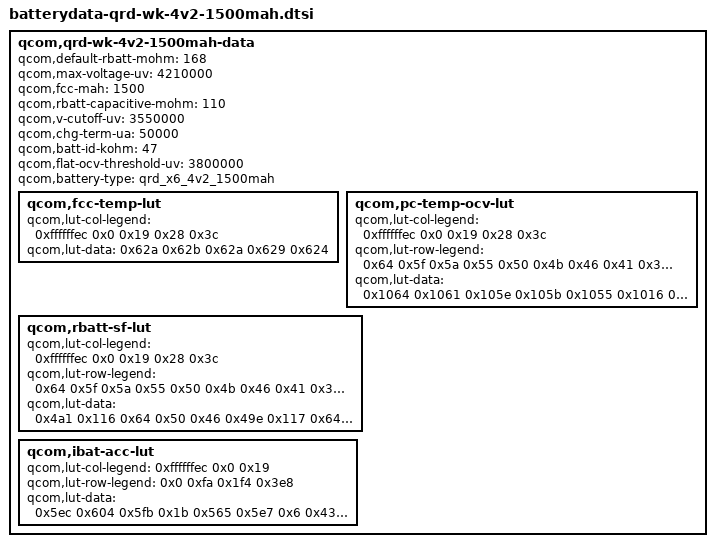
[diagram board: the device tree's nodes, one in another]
/* Copyright (c) 2014, The Linux Foundation. All rights reserved.
 *
 * This program is free software; you can redistribute it and/or modify
 * it under the terms of the GNU General Public License version 2 and
 * only version 2 as published by the Free Software Foundation.
 *
 * This program is distributed in the hope that it will be useful,
 * but WITHOUT ANY WARRANTY; without even the implied warranty of
 * MERCHANTABILITY or FITNESS FOR A PARTICULAR PURPOSE.  See the
 * GNU General Public License for more details.
 */

qcom,qrd-wk-4v2-1500mah-data {
	qcom,default-rbatt-mohm = <168>;
	qcom,max-voltage-uv = <4210000>;
	qcom,fcc-mah = <1500>;
	qcom,rbatt-capacitive-mohm = <110>;
	qcom,v-cutoff-uv = <3550000>;
	qcom,chg-term-ua = <50000>;
	qcom,batt-id-kohm = <47>;
	qcom,flat-ocv-threshold-uv = <3800000>;
	qcom,battery-type = "qrd_x6_4v2_1500mah";

	qcom,fcc-temp-lut {
		qcom,lut-col-legend = <0xffffffec 0x0 0x19 0x28 0x3c>;
		qcom,lut-data = <0x62a 0x62b 0x62a 0x629 0x624>;
	};

	qcom,pc-temp-ocv-lut {
		qcom,lut-col-legend = <0xffffffec 0x0 0x19 0x28 0x3c>;
		qcom,lut-row-legend = <0x64 0x5f 0x5a 0x55 0x50 0x4b 0x46 0x41 0x3c 0x37 0x32 0x2d 0x28 0x23 0x1e 0x19 0x14 0x10 0xd 0xb 0xa 0x9 0x8 0x7 0x6 0x5 0x4 0x3 0x2 0x1 0x0>;
		qcom,lut-data = <0x1064 0x1061 0x105e 0x105b 0x1055 0x1016 0x1022 0x1022 0x1020 0x101c 0xfdf 0xff0 0xff1 0xfef 0xfec 0xfa8 0xfc2 0xfc5 0xfc3 0xfc0 0xf76 0xf95 0xf9d 0xf9b 0xf98 0xf50 0xf6e 0xf79 0xf78 0xf74 0xf2d 0xf4a 0xf5a 0xf58 0xf54 0xf0d 0xf29 0xf3b 0xf3b 0xf37 0xef2 0xf0c 0xf19 0xf1b 0xf19 0xedc 0xef3 0xef7 0xef8 0xef6 0xecb 0xedd 0xedf 0xede 0xedd 0xebd 0xecc 0xece 0xece 0xecc 0xeaf 0xebe 0xec2 0xec2 0xec0 0xea1 0xeb3 0xeba 0xeb8 0xeb5 0xe92 0xea7 0xeb3 0xeae 0xea7 0xe81 0xe96 0xea6 0xe9f 0xe91 0xe6d 0xe84 0xe93 0xe8a 0xe7d 0xe59 0xe79 0xe78 0xe70 0xe64 0xe46 0xe6e 0xe61 0xe58 0xe4c 0xe34 0xe66 0xe5b 0xe53 0xe48 0xe29 0xe61 0xe58 0xe51 0xe46 0xe1e 0xe5b 0xe56 0xe4f 0xe44 0xe10 0xe55 0xe53 0xe4c 0xe41 0xdff 0xe4c 0xe4e 0xe47 0xe3c 0xdea 0xe40 0xe45 0xe3d 0xe30 0xdce 0xe2b 0xe30 0xe25 0xe13 0xdab 0xe05 0xe04 0xdfa 0xde6 0xd78 0xdce 0xdc6 0xdbc 0xda9 0xd27 0xd7e 0xd73 0xd6a 0xd57 0xca3 0xcfd 0xcf9 0xceb 0xcd7 0xbc0 0xbb8 0xbd9 0xbb8 0xbb8>;
	};

	qcom,rbatt-sf-lut {
		qcom,lut-col-legend = <0xffffffec 0x0 0x19 0x28 0x3c>;
		qcom,lut-row-legend = <0x64 0x5f 0x5a 0x55 0x50 0x4b 0x46 0x41 0x3c 0x37 0x32 0x2d 0x28 0x23 0x1e 0x19 0x14 0x10 0xd 0xb 0xa 0x9 0x8 0x7 0x6 0x5 0x4 0x3 0x2 0x1>;
		qcom,lut-data = <0x4a1 0x116 0x64 0x50 0x46 0x49e 0x117 0x64 0x50 0x46 0x470 0x11c 0x66 0x51 0x47 0x445 0x120 0x69 0x53 0x48 0x427 0x11f 0x6d 0x55 0x4a 0x41d 0x11c 0x72 0x58 0x4c 0x415 0x119 0x78 0x5c 0x50 0x415 0x115 0x7e 0x61 0x53 0x419 0x113 0x77 0x62 0x55 0x425 0x112 0x6a 0x58 0x4e 0x43b 0x113 0x65 0x52 0x49 0x458 0x116 0x66 0x53 0x4a 0x47e 0x11a 0x68 0x56 0x4d 0x4ab 0x121 0x6c 0x58 0x50 0x4e4 0x128 0x70 0x58 0x4f 0x527 0x12b 0x71 0x57 0x4b 0x56d 0x139 0x71 0x56 0x4b 0x582 0x149 0x6c 0x55 0x4b 0x57c 0x14b 0x67 0x51 0x49 0x5eb 0x15c 0x69 0x53 0x4b 0x658 0x169 0x6b 0x56 0x4c 0x709 0x177 0x6f 0x58 0x4e 0x7fe 0x18b 0x74 0x5a 0x4f 0x956 0x1a4 0x79 0x5d 0x51 0xb4a 0x1c3 0x7d 0x5e 0x50 0xea1 0x1ee 0x7d 0x5c 0x4e 0x13c7 0x231 0x7b 0x5b 0x4f 0x91fa 0x2b8 0x82 0x60 0x53 0x2fc7 0x3d0 0x92 0x69 0x58 0x5f8f 0x728 0xc0 0x86 0x69>;
	};

	qcom,ibat-acc-lut {
		qcom,lut-col-legend = <0xffffffec 0x0 0x19>;
		qcom,lut-row-legend = <0x0 0xfa 0x1f4 0x3e8>;
		qcom,lut-data = <0x5ec 0x604 0x5fb 0x1b 0x565 0x5e7 0x6 0x430 0x5d0 0x6 0x1c8 0x535>;
	};
};
